VERSION ""

NS_ :

BS_:

BU_: ABS ENGINE ETACS SAS SHIFT TRANSMISSION

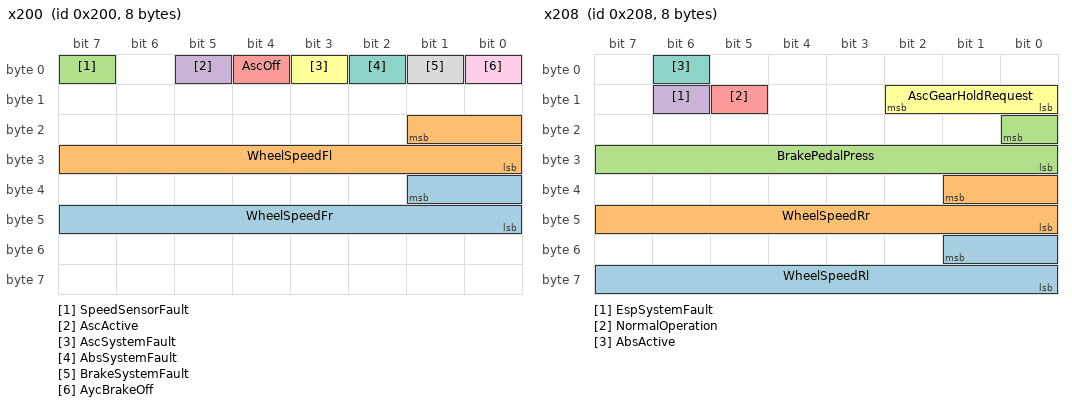
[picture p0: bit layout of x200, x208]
BO_ 512 x200: 8 ABS
 SG_ WheelSpeedFr : 33|10@0+ (0.5,0) [0|511.5] "RPM" Vector__XXX
 SG_ WheelSpeedFl : 17|10@0+ (0.5,0) [0|511.5] "RPM" Vector__XXX
 SG_ SpeedSensorFault : 7|1@0+ (1,0) [0|1] "" Vector__XXX
 SG_ AscActive : 5|1@0+ (1,0) [0|1] "" Vector__XXX
 SG_ AscOff : 4|1@0+ (1,0) [0|1] "" Vector__XXX
 SG_ AscSystemFault : 3|1@0+ (1,0) [0|1] "" Vector__XXX
 SG_ AbsSystemFault : 2|1@0+ (1,0) [0|1] "" Vector__XXX
 SG_ BrakeSystemFault : 1|1@0+ (1,0) [0|1] "" Vector__XXX
 SG_ AycBrakeOff : 0|1@0+ (1,0) [0|1] "" Vector__XXX

BO_ 520 x208: 8 ABS
 SG_ WheelSpeedRl : 49|10@0+ (0.5,0) [0|511.5] "RPM" Vector__XXX
 SG_ WheelSpeedRr : 33|10@0+ (0.5,0) [0|511.5] "RPM" Vector__XXX
 SG_ BrakePedalPress : 16|9@0+ (1,0) [0|1] "" Vector__XXX
 SG_ EspSystemFault : 14|1@0+ (1,0) [0|1] "" Vector__XXX
 SG_ NormalOperation : 13|1@0+ (1,0) [0|7] "" Vector__XXX
 SG_ AscGearHoldRequest : 10|3@0+ (1,0) [0|7] "" Vector__XXX
 SG_ AbsActive : 6|1@0+ (1,0) [0|1] "" Vector__XXX

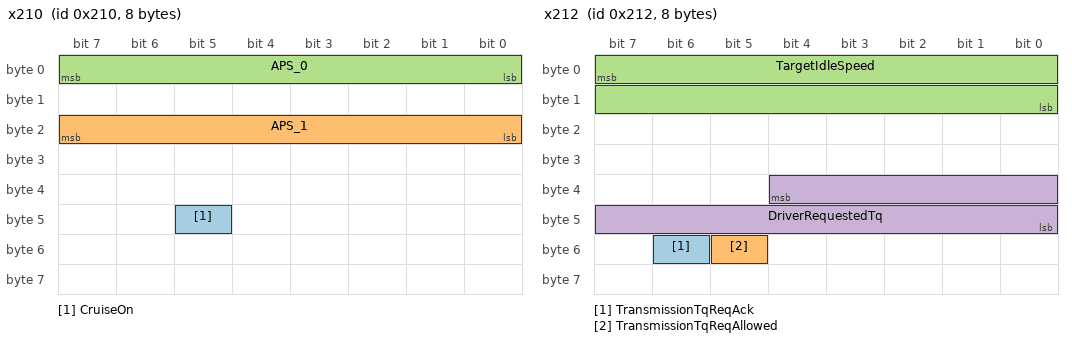
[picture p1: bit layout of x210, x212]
BO_ 528 x210: 8 ENGINE
 SG_ CruiseOn : 45|1@0+ (1,0) [0|7] "" Vector__XXX
 SG_ APS_1 : 23|8@0+ (0.4,0) [0|102] "%" Vector__XXX
 SG_ APS_0 : 7|8@0+ (1,0) [0|1] "" Vector__XXX

BO_ 530 x212: 8 ENGINE
 SG_ TransmissionTqReqAck : 54|1@0- (1,0) [0|0] "flag" Vector__XXX
 SG_ TransmissionTqReqAllowed : 53|1@0- (1,0) [0|0] "flag" Vector__XXX
 SG_ TargetIdleSpeed : 7|16@0+ (1,0) [0|65535] "RPM" Vector__XXX
 SG_ DriverRequestedTq : 36|13@0+ (0.125,0) [0|0] "" Vector__XXX

BO_ 533 x215: 7 ABS
 SG_ MasterVehicleSpeed : 7|16@0+ (0.007812,0) [0|511.95942] "km/h" Vector__XXX

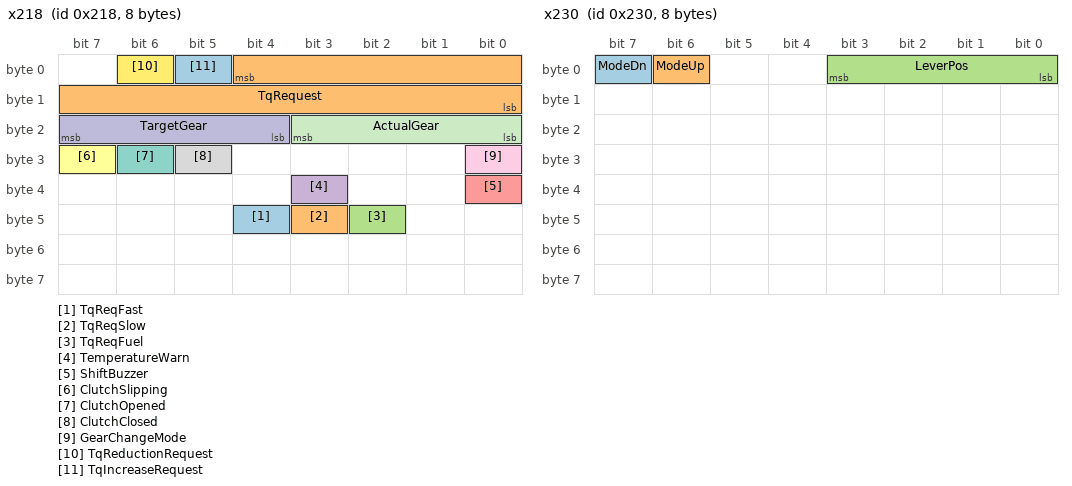
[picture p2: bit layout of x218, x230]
BO_ 536 x218: 8 TRANSMISSION
 SG_ TqReqFast : 44|1@0- (1,0) [0|0] "flag" Vector__XXX
 SG_ TqReqSlow : 43|1@0- (1,0) [0|0] "flag" Vector__XXX
 SG_ TqReqFuel : 42|1@0- (1,0) [0|0] "flag" Vector__XXX
 SG_ TemperatureWarn : 35|1@0- (1,0) [0|0] "ON/OFF" Vector__XXX
 SG_ ShiftBuzzer : 32|1@0- (1,0) [0|0] "ON/OFF" Vector__XXX
 SG_ ClutchSlipping : 31|1@0- (1,0) [0|0] "flag" Vector__XXX
 SG_ ClutchOpened : 30|1@0- (1,0) [0|0] "flag" Vector__XXX
 SG_ ClutchClosed : 29|1@0- (1,0) [0|0] "flag" Vector__XXX
 SG_ GearChangeMode : 24|1@0- (1,0) [0|0] "M/D" Vector__XXX
 SG_ TargetGear : 23|4@0+ (1,0) [0|15] "gear" Vector__XXX
 SG_ ActualGear : 19|4@0+ (1,0) [0|15] "gear" Vector__XXX
 SG_ TqReductionRequest : 6|1@0- (1,0) [0|0] "flag" Vector__XXX
 SG_ TqIncreaseRequest : 5|1@0- (1,0) [0|0] "flag" Vector__XXX
 SG_ TqRequest : 4|13@0+ (0.125,0) [0|1023.875] "Nm" Vector__XXX

BO_ 560 x230: 8 SHIFT
 SG_ ModeDn : 7|1@0- (1,0) [0|0] "ON/OFF" Vector__XXX
 SG_ ModeUp : 6|1@0- (1,0) [0|0] "ON/OFF" Vector__XXX
 SG_ LeverPos : 3|4@0+ (1,0) [0|15] "" Vector__XXX

BO_ 566 x236: 8 SAS
 SG_ SteeringAcceleration : 23|16@0+ (1,0) [0|1] "" Vector__XXX
 SG_ SteeringAngle : 7|16@0+ (1,0) [0|1] "" Vector__XXX

BO_ 584 x248: 8 ETACS
 SG_ ParkingBrake : 27|1@0+ (1,0) [0|1] "" Vector__XXX
 SG_ HazardLight : 6|1@0+ (1,0) [0|1] "" Vector__XXX

BO_ 613 x265: 8 TRANSMISSION
 SG_ TransmissionLossTorque : 52|13@0+ (0.125,0) [0|1023.875] "Nm" Vector__XXX
 SG_ IdleSpdIncreaseReq : 7|1@0+ (1,0) [0|1] "ON/OFF" Vector__XXX

BO_ 776 x308: 8 ENGINE
 SG_ MinimumTorqueReachedByIgnit_0000 : 44|13@0+ (0.125,0) [0|1023.875] "Nm" Vector__XXX
 SG_ EngineRevs : 15|16@0+ (1,0) [0|65535] "RPM" Vector__XXX

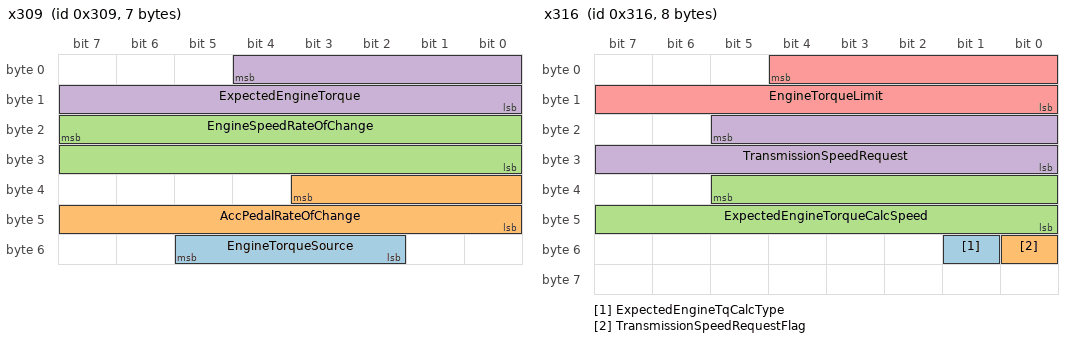
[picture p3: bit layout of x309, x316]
BO_ 777 x309: 7 ENGINE
 SG_ EngineTorqueSource : 53|4@0+ (1,0) [0|15] "" Vector__XXX
 SG_ AccPedalRateOfChange : 35|12@0+ (1,-2048) [-2048|2047] "" Vector__XXX
 SG_ EngineSpeedRateOfChange : 23|16@0+ (1,-32768) [-32768|32767] "" Vector__XXX
 SG_ ExpectedEngineTorque : 4|13@0+ (0.125,0) [0|1023.875] "Nm" Vector__XXX

BO_ 790 x316: 8 TRANSMISSION
 SG_ ExpectedEngineTqCalcType : 49|1@0- (1,0) [-1|0] "" Vector__XXX
 SG_ TransmissionSpeedRequestFlag : 48|1@0- (1,0) [-1|0] "flag" Vector__XXX
 SG_ ExpectedEngineTorqueCalcSpeed : 37|14@0+ (0.5,0) [0|8191.5] "RPM" Vector__XXX
 SG_ TransmissionSpeedRequest : 21|14@0+ (1,0) [0|16383] "RPM" Vector__XXX
 SG_ EngineTorqueLimit : 4|13@0+ (0.125,0) [0|1023.875] "Nm" Vector__XXX

BO_ 824 x338: 8 TRANSMISSION
 SG_ UnkSignal : 31|16@0+ (1,0) [0|65535] "" Vector__XXX
 SG_ OutputShaftSpeed : 7|16@0+ (0.125,0) [0|8191.875] "RPM" Vector__XXX

BO_ 869 x365: 8 TRANSMISSION
 SG_ EngineSpeedLimit : 63|8@0+ (30,0) [0|7650] "RPM" Vector__XXX
 SG_ TransmissionRatio : 39|8@0+ (1,0) [0|255] "x" Vector__XXX

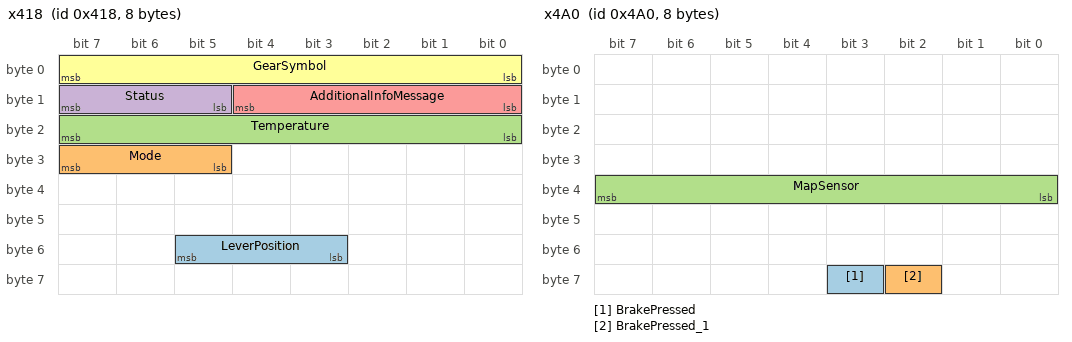
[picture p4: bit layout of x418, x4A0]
BO_ 1048 x418: 8 TRANSMISSION
 SG_ LeverPosition : 53|3@0+ (1,0) [0|7] "" Vector__XXX
 SG_ Mode : 31|3@0+ (1,0) [0|1] "" Vector__XXX
 SG_ Temperature : 23|8@0+ (1,0) [0|1] "" Vector__XXX
 SG_ Status : 15|3@0+ (1,0) [0|1] "" Vector__XXX
 SG_ AdditionalInfoMessage : 12|5@0+ (1,0) [0|1] "" Vector__XXX
 SG_ GearSymbol : 7|8@0+ (1,0) [0|1] "" Vector__XXX

BO_ 1184 x4A0: 8 ENGINE
 SG_ BrakePressed : 59|1@0+ (1,0) [0|1] "" Vector__XXX
 SG_ BrakePressed_1 : 58|1@0+ (1,0) [0|1] "" Vector__XXX
 SG_ MapSensor : 39|8@0+ (1,0) [0|255] "kpa" Vector__XXX

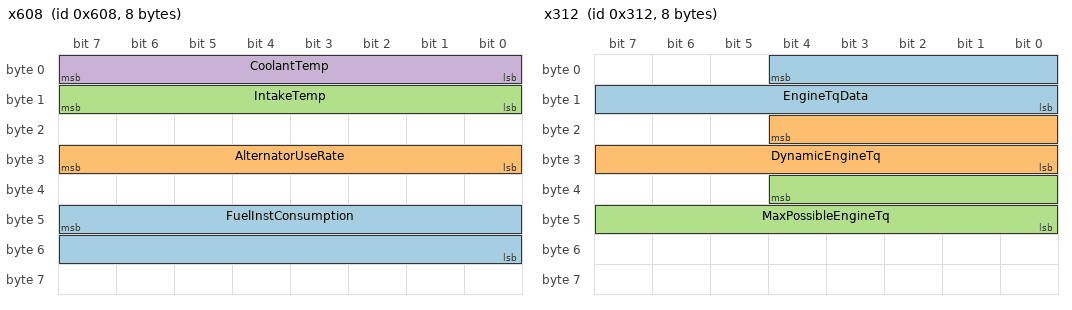
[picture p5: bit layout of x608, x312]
BO_ 1544 x608: 8 ENGINE
 SG_ FuelInstConsumption : 47|16@0+ (1,0) [0|1] "" Vector__XXX
 SG_ AlternatorUseRate : 31|8@0+ (1,0) [0|1] "" Vector__XXX
 SG_ IntakeTemp : 15|8@0+ (1,0) [0|1] "" Vector__XXX
 SG_ CoolantTemp : 7|8@0+ (1,-40) [-40|215] "C" Vector__XXX

BO_ 786 x312: 8 ENGINE
 SG_ EngineTqData : 4|13@0+ (0.125,0) [0|0] "" Vector__XXX
 SG_ DynamicEngineTq : 20|13@0+ (0.125,0) [0|0] "" Vector__XXX
 SG_ MaxPossibleEngineTq : 36|13@0+ (0.125,0) [0|0] "" Vector__XXX

CM_ SG_ 560 LeverPos "8 - parking, 7 - rear, 6 - N, 5 - D, E - manual, A - Manual UP, 9 - manual DN";
CM_ SG_ 777 EngineTorqueSource "1-idle,2-dr req,3-cruise,B-engine protection";
BA_DEF_ SG_  "SystemSignalLongSymbol" STRING ;
BA_DEF_DEF_  "SystemSignalLongSymbol" "";
BA_ "SystemSignalLongSymbol" SG_ 776 MinimumTorqueReachedByIgnit_0000 "MinimumTorqueReachedByIgnitionRetard";
VAL_ 520 AscGearHoldRequest 1 "TCL" 3 "ASC" 4 "Requested" 5 "HoldAndLU" ;
